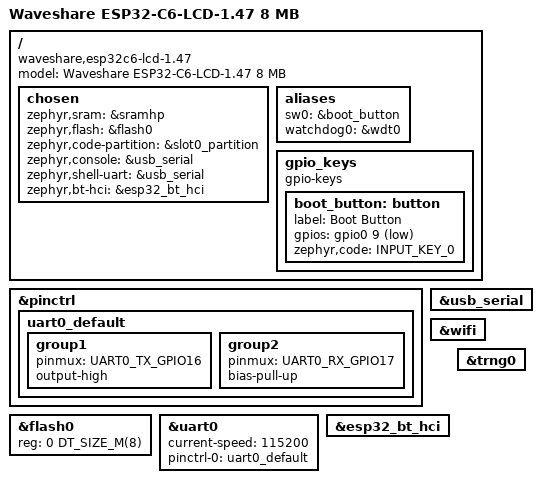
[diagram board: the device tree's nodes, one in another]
/*
 * Copyright (c) 2026 Embeint Holdings Pty Ltd
 * SPDX-License-Identifier: FSL-1.1-ALv2
 */

/dts-v1/;

#include <espressif/esp32c6/esp32c6_wroom_n8.dtsi>
#include <espressif/partitions_0x0_default_8M.dtsi>
#include <zephyr/dt-bindings/input/input-event-codes.h>
#include <zephyr/dt-bindings/pinctrl/esp-pinctrl-common.h>
#include <zephyr/dt-bindings/pinctrl/esp32c6-pinctrl.h>
#include <zephyr/dt-bindings/pinctrl/esp32c6-gpio-sigmap.h>

/ {
	model = "Waveshare ESP32-C6-LCD-1.47 8 MB";
	compatible = "waveshare,esp32c6-lcd-1.47", "espressif,esp32c6";
	chosen {
		zephyr,sram = &sramhp;
		zephyr,flash = &flash0;
		zephyr,code-partition = &slot0_partition;
		zephyr,console = &usb_serial;
		zephyr,shell-uart = &usb_serial;
		zephyr,bt-hci = &esp32_bt_hci;
	};
	aliases {
		sw0 = &boot_button;
		watchdog0 = &wdt0;
	};
	gpio_keys {
		compatible = "gpio-keys";
		boot_button: button {
			label = "Boot Button";
			gpios = <&gpio0 9 (GPIO_PULL_UP | GPIO_ACTIVE_LOW)>;
			zephyr,code = <INPUT_KEY_0>;
		};
	};
};

&pinctrl {
	uart0_default: uart0_default {
		group1 {
			pinmux = <UART0_TX_GPIO16>;
			output-high;
		};
		group2 {
			pinmux = <UART0_RX_GPIO17>;
			bias-pull-up;
		};
	};
};

&flash0 {
	reg = <0 DT_SIZE_M(8)>;
};

&usb_serial {
	status = "okay";
};

&uart0 {
	status = "okay";
	current-speed = <115200>;
	pinctrl-0 = <&uart0_default>;
	pinctrl-names = "default";
};

&wifi {
	status = "okay";
};

&esp32_bt_hci {
	status = "okay";
};

&trng0 {
	status = "okay";
};
